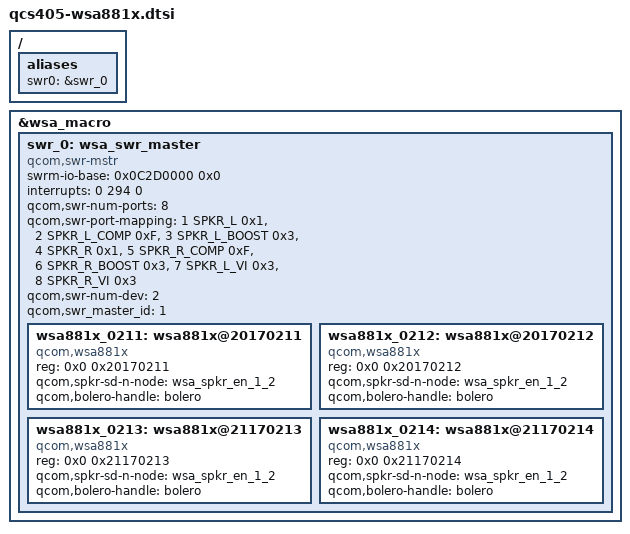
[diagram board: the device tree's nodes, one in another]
/* Copyright (c) 2018-2019, The Linux Foundation. All rights reserved.
 *
 * This program is free software; you can redistribute it and/or modify
 * it under the terms of the GNU General Public License version 2 and
 * only version 2 as published by the Free Software Foundation.
 *
 * This program is distributed in the hope that it will be useful,
 * but WITHOUT ANY WARRANTY; without even the implied warranty of
 * MERCHANTABILITY or FITNESS FOR A PARTICULAR PURPOSE.  See the
 * GNU General Public License for more details.
 */

/{
	aliases {
		swr0 = &swr_0;
	};
};

#include <dt-bindings/sound/audio-codec-port-types.h>

&wsa_macro {
	swr_0: wsa_swr_master {
		compatible = "qcom,swr-mstr";
		#address-cells = <2>;
		#size-cells = <0>;
		swrm-io-base = <0x0C2D0000 0x0>;
		interrupts = <0 294 0>;
		interrupt-names = "swr_master_irq";
		qcom,swr-num-ports = <8>;
		qcom,swr-port-mapping = <1 SPKR_L 0x1>,
			<2 SPKR_L_COMP 0xF>, <3 SPKR_L_BOOST 0x3>,
			<4 SPKR_R 0x1>, <5 SPKR_R_COMP 0xF>,
			<6 SPKR_R_BOOST 0x3>, <7 SPKR_L_VI 0x3>,
			<8 SPKR_R_VI 0x3>;
		qcom,swr-num-dev = <2>;
		qcom,swr_master_id = <1>;
		wsa881x_0211: wsa881x@20170211 {
			compatible = "qcom,wsa881x";
			reg = <0x0 0x20170211>;
			qcom,spkr-sd-n-node = <&wsa_spkr_en_1_2>;
			qcom,bolero-handle = <&bolero>;
		};

		wsa881x_0212: wsa881x@20170212 {
			compatible = "qcom,wsa881x";
			reg = <0x0 0x20170212>;
			qcom,spkr-sd-n-node = <&wsa_spkr_en_1_2>;
			qcom,bolero-handle = <&bolero>;
		};

		wsa881x_0213: wsa881x@21170213 {
			compatible = "qcom,wsa881x";
			reg = <0x0 0x21170213>;
			qcom,spkr-sd-n-node = <&wsa_spkr_en_1_2>;
			qcom,bolero-handle = <&bolero>;
		};

		wsa881x_0214: wsa881x@21170214 {
			compatible = "qcom,wsa881x";
			reg = <0x0 0x21170214>;
			qcom,spkr-sd-n-node = <&wsa_spkr_en_1_2>;
			qcom,bolero-handle = <&bolero>;
		};
	};
};
